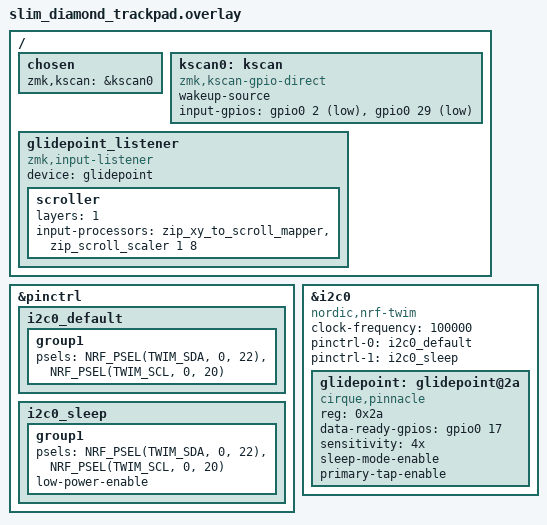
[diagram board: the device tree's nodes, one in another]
/*
 * Cirque I2C breakout: SDA D4/P0.22, SCL D3/P0.20, power and ground through FFC.
 * Separate direct DR wire D2/P0.17; keys D19/P0.02 and D20/P0.29.
 *
 * SPDX-License-Identifier: MIT
 */

#include <zephyr/dt-bindings/input/input-event-codes.h>
#include <input/processors.dtsi>

/ {
    chosen {
        zmk,kscan = &kscan0;
    };

    kscan0: kscan {
        compatible = "zmk,kscan-gpio-direct";
        wakeup-source;
        input-gpios
            = <&gpio0 2 (GPIO_ACTIVE_LOW | GPIO_PULL_UP)>
            , <&gpio0 29 (GPIO_ACTIVE_LOW | GPIO_PULL_UP)>
            ;
    };

    glidepoint_listener: glidepoint_listener {
        compatible = "zmk,input-listener";
        device = <&glidepoint>;

        /* layer 1 (the right key held): the pad scrolls */
        scroller {
            layers = <1>;
            input-processors = <&zip_xy_to_scroll_mapper>, <&zip_scroll_scaler 1 8>;
        };
    };
};

&pinctrl {
    i2c0_default: i2c0_default {
        group1 {
            psels = <NRF_PSEL(TWIM_SDA, 0, 22)>,
                    <NRF_PSEL(TWIM_SCL, 0, 20)>;
        };
    };

    i2c0_sleep: i2c0_sleep {
        group1 {
            psels = <NRF_PSEL(TWIM_SDA, 0, 22)>,
                    <NRF_PSEL(TWIM_SCL, 0, 20)>;
            low-power-enable;
        };
    };
};

&i2c0 {
    status = "okay";
    compatible = "nordic,nrf-twim";
    clock-frequency = <100000>;
    pinctrl-0 = <&i2c0_default>;
    pinctrl-1 = <&i2c0_sleep>;
    pinctrl-names = "default", "sleep";

    glidepoint: glidepoint@2a {
        compatible = "cirque,pinnacle";
        reg = <0x2a>;
        status = "okay";
        data-ready-gpios = <&gpio0 17 GPIO_ACTIVE_HIGH>;
        sensitivity = "4x";
        sleep-mode-enable;
        primary-tap-enable;
        /* Validate orientation and tap/sleep behaviour on the actual pad. */
    };
};
